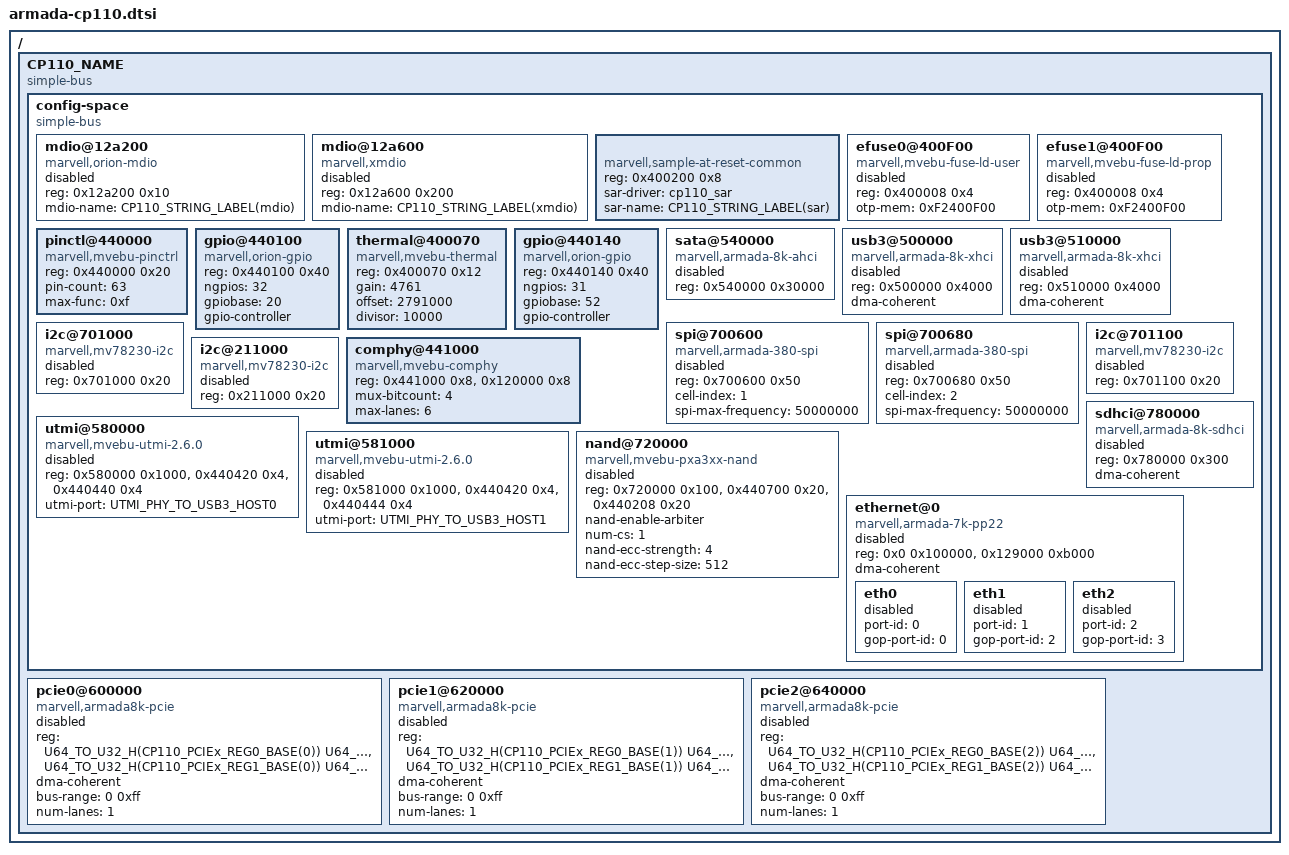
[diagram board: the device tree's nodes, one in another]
// SPDX-License-Identifier: GPL-2.0+
/*
 * Copyright (C) 2018 Marvell International Ltd.
 */

/*
 * Generic Device Tree describing Marvell Armada CP-110 device
 */
#include <dt-bindings/comphy/comphy_data.h>

#define U64_TO_U32_H(addr)		(((addr) >> 32) & 0xffffffff)
#define U64_TO_U32_L(addr)		((addr) & 0xffffffff)

#define CP110_PCIEx_REG0_BASE(iface)	\
	(CP110_BASE + 0x600000 + (iface) * 0x20000)
#define CP110_PCIEx_REG1_BASE(iface)	\
	(CP110_PCIEx_CPU_MEM_BASE(iface) + CP110_PCIE_MEM_SIZE)
/ {
	CP110_NAME {
		#address-cells = <2>;
		#size-cells = <2>;
		compatible = "simple-bus";
		ranges;

		config-space {
			#address-cells = <1>;
			#size-cells = <1>;
			compatible = "simple-bus";
			ranges = <0x0 U64_TO_U32_H(CP110_BASE) U64_TO_U32_L(CP110_BASE) 0x2000000>;

			CP110_LABEL(mdio): mdio@12a200 {
				#address-cells = <1>;
				#size-cells = <0>;
				compatible = "marvell,orion-mdio";
				reg = <0x12a200 0x10>;
				mdio-name = CP110_STRING_LABEL(mdio);
				status = "disabled";
			};

			CP110_LABEL(xmdio): mdio@12a600 {
				#address-cells = <1>;
				#size-cells = <0>;
				compatible = "marvell,xmdio";
				reg = <0x12a600 0x200>;
				mdio-name = CP110_STRING_LABEL(xmdio);
				status = "disabled";
			};

			CP110_LABEL(sar-reg) {
				compatible = "marvell,sample-at-reset-common",
					     "marvell,sample-at-reset-cp110";
				reg = <0x400200 0x8>;
				sar-driver = "cp110_sar";
				sar-name = CP110_STRING_LABEL(sar);
				status = "okay";
			};

			CP110_LABEL(ld_efuse0): efuse0@400F00 {
				compatible = "marvell,mvebu-fuse-ld-user";
				reg = <0x400008 0x4>;
				otp-mem = <0xF2400F00>;
				status = "disabled";
			};

			CP110_LABEL(ld_efuse1): efuse1@400F00 {
				compatible = "marvell,mvebu-fuse-ld-prop";
				reg = <0x400008 0x4>;
				otp-mem = <0xF2400F00>;
				status = "disabled";
			};

			CP110_LABEL(pinctl): pinctl@440000 {
				compatible = "marvell,mvebu-pinctrl";
				reg = <0x440000 0x20>;
				pin-count = <63>;
				max-func = <0xf>;
			};

			CP110_LABEL(gpio0): gpio@440100 {
				compatible = "marvell,orion-gpio";
				reg = <0x440100 0x40>;
				ngpios = <32>;
				gpiobase = <20>;
				gpio-controller;
				#gpio-cells = <2>;
			};

			CP110_LABEL(thermal): thermal@400070 {
				compatible = "marvell,mvebu-thermal", "marvell,thermal-sensor";
				reg = <0x400070 0x12>;
				gain = <4761>;
				offset = <2791000>;
				divisor = <10000>;
				status = "okay";
			};

			CP110_LABEL(gpio1): gpio@440140 {
				compatible = "marvell,orion-gpio";
				reg = <0x440140 0x40>;
				ngpios = <31>;
				gpiobase = <52>;
				gpio-controller;
				#gpio-cells = <2>;
			};

			CP110_LABEL(sata0): sata@540000 {
				compatible = "marvell,armada-8k-ahci";
				reg = <0x540000 0x30000>;
				status = "disabled";
			};

			CP110_LABEL(usb3_0): usb3@500000 {
				compatible = "marvell,armada-8k-xhci",
					     "generic-xhci";
				reg = <0x500000 0x4000>;
				dma-coherent;
				status = "disabled";
			};

			CP110_LABEL(usb3_1): usb3@510000 {
				compatible = "marvell,armada-8k-xhci",
					     "generic-xhci";
				reg = <0x510000 0x4000>;
				dma-coherent;
				status = "disabled";
			};

			CP110_LABEL(spi0): spi@700600 {
				compatible = "marvell,armada-380-spi";
				reg = <0x700600 0x50>;
				#address-cells = <0x1>;
				#size-cells = <0x0>;
				cell-index = <1>;
				spi-max-frequency = <50000000>;
				status = "disabled";
			};

			CP110_LABEL(spi1): spi@700680 {
				compatible = "marvell,armada-380-spi";
				reg = <0x700680 0x50>;
				#address-cells = <1>;
				#size-cells = <0>;
				cell-index = <2>;
				spi-max-frequency = <50000000>;
				status = "disabled";
			};

			CP110_LABEL(i2c0): i2c@701000 {
				compatible = "marvell,mv78230-i2c";
				reg = <0x701000 0x20>;
				#address-cells = <1>;
				#size-cells = <0>;
				status = "disabled";
			};

			CP110_LABEL(i2c1): i2c@701100 {
				compatible = "marvell,mv78230-i2c";
				reg = <0x701100 0x20>;
				#address-cells = <1>;
				#size-cells = <0>;
				status = "disabled";
			};

			CP110_LABEL(mss_i2c0): i2c@211000 {
				compatible = "marvell,mv78230-i2c";
				reg = <0x211000 0x20>;
				#address-cells = <1>;
				#size-cells = <0>;
				status = "disabled";
			};

			CP110_LABEL(comphy): comphy@441000 {
				compatible = "marvell,mvebu-comphy", "marvell,comphy-cp110";
				reg = <0x441000 0x8>,
				      <0x120000 0x8>;
				mux-bitcount = <4>;
				max-lanes = <6>;
			};

			CP110_LABEL(utmi0): utmi@580000 {
				compatible = "marvell,mvebu-utmi-2.6.0";
				reg = <0x580000 0x1000>,	/* utmi-unit */
				      <0x440420 0x4>,		/* usb-cfg */
				      <0x440440 0x4>;		/* utmi-cfg */
				utmi-port = <UTMI_PHY_TO_USB3_HOST0>;
				status = "disabled";
			};

			CP110_LABEL(utmi1): utmi@581000 {
				compatible = "marvell,mvebu-utmi-2.6.0";
				reg = <0x581000 0x1000>,	/* utmi-unit */
				      <0x440420 0x4>,		/* usb-cfg */
				      <0x440444 0x4>;		/* utmi-cfg */
				utmi-port = <UTMI_PHY_TO_USB3_HOST1>;
				status = "disabled";
			};

			CP110_LABEL(sdhci0): sdhci@780000 {
				compatible = "marvell,armada-8k-sdhci";
				reg = <0x780000 0x300>;
				dma-coherent;
				status = "disabled";
			};

			CP110_LABEL(nand): nand@720000 {
				compatible = "marvell,mvebu-pxa3xx-nand";
				reg = <0x720000 0x100>,
				      <0x440700 0x20>,
				      <0x440208 0x20>;
				reg-names = "ctrl_base",
					    "flash_clock",
					    "dev_mux";
				#address-cells = <1>;

				nand-enable-arbiter;
				num-cs = <1>;
				nand-ecc-strength = <4>;
				nand-ecc-step-size = <512>;
				status = "disabled";
			};

			CP110_LABEL(ethernet): ethernet@0 {
				compatible = "marvell,armada-7k-pp22";
				reg = <0x0 0x100000>, <0x129000 0xb000>;
				status = "disabled";
				dma-coherent;

				CP110_LABEL(eth0): eth0 {
					port-id = <0>;
					gop-port-id = <0>;
					status = "disabled";
				};

				CP110_LABEL(eth1): eth1 {
					port-id = <1>;
					gop-port-id = <2>;
					status = "disabled";
				};

				CP110_LABEL(eth2): eth2 {
					port-id = <2>;
					gop-port-id = <3>;
					status = "disabled";
				};
			};
		};

		CP110_LABEL(pcie0): pcie0@600000 {
			compatible = "marvell,armada8k-pcie", "snps,dw-pcie";
			reg =
			   <U64_TO_U32_H(CP110_PCIEx_REG0_BASE(0)) U64_TO_U32_L(CP110_PCIEx_REG0_BASE(0)) 0 0x10000>,
			   /* Last 512KB of mem space */
			   <U64_TO_U32_H(CP110_PCIEx_REG1_BASE(0)) U64_TO_U32_L(CP110_PCIEx_REG1_BASE(0)) 0 0x80000>;
			reg-names = "ctrl", "config";
			#address-cells = <3>;
			#size-cells = <2>;
			device_type = "pci";
			dma-coherent;

			bus-range = <0 0xff>;
			ranges =
				/* downstream I/O */
				<0x81000000 U64_TO_U32_H(CP110_PCIEx_BUS_IO_BASE(0))
				U64_TO_U32_L(CP110_PCIEx_BUS_IO_BASE(0)) U64_TO_U32_H(CP110_PCIEx_CPU_IO_BASE(0))
				U64_TO_U32_L(CP110_PCIEx_CPU_IO_BASE(0)) 0 0x10000
				/* non-prefetchable memory */
				CP110_PCIE_BUS_MEM_CFG U64_TO_U32_H(CP110_PCIEx_BUS_MEM_BASE(0))
				U64_TO_U32_L(CP110_PCIEx_BUS_MEM_BASE(0)) U64_TO_U32_H(CP110_PCIEx_CPU_MEM_BASE(0))
				U64_TO_U32_L(CP110_PCIEx_CPU_MEM_BASE(0)) U64_TO_U32_H(CP110_PCIE_MEM_SIZE)
				U64_TO_U32_L(CP110_PCIE_MEM_SIZE)>;
			num-lanes = <1>;
			status = "disabled";
		};

		CP110_LABEL(pcie1): pcie1@620000 {
			compatible = "marvell,armada8k-pcie", "snps,dw-pcie";
			reg =
			   <U64_TO_U32_H(CP110_PCIEx_REG0_BASE(1)) U64_TO_U32_L(CP110_PCIEx_REG0_BASE(1)) 0 0x10000>,
			   /* Last 512KB of mem space */
			   <U64_TO_U32_H(CP110_PCIEx_REG1_BASE(1)) U64_TO_U32_L(CP110_PCIEx_REG1_BASE(1)) 0 0x80000>;
			reg-names = "ctrl", "config";
			#address-cells = <3>;
			#size-cells = <2>;
			device_type = "pci";
			dma-coherent;

			bus-range = <0 0xff>;
			ranges =
				/* downstream I/O */
				<0x81000000 U64_TO_U32_H(CP110_PCIEx_BUS_IO_BASE(1))
				U64_TO_U32_L(CP110_PCIEx_BUS_IO_BASE(1)) U64_TO_U32_H(CP110_PCIEx_CPU_IO_BASE(1))
				U64_TO_U32_L(CP110_PCIEx_CPU_IO_BASE(1)) 0 0x10000
				/* non-prefetchable memory */
				CP110_PCIE_BUS_MEM_CFG U64_TO_U32_H(CP110_PCIEx_BUS_MEM_BASE(1))
				U64_TO_U32_L(CP110_PCIEx_BUS_MEM_BASE(1)) U64_TO_U32_H(CP110_PCIEx_CPU_MEM_BASE(1))
				U64_TO_U32_L(CP110_PCIEx_CPU_MEM_BASE(1)) U64_TO_U32_H(CP110_PCIE_MEM_SIZE)
				U64_TO_U32_L(CP110_PCIE_MEM_SIZE)>;
			num-lanes = <1>;
			status = "disabled";
		};

		CP110_LABEL(pcie2): pcie2@640000 {
			compatible = "marvell,armada8k-pcie", "snps,dw-pcie";
			reg =
			   <U64_TO_U32_H(CP110_PCIEx_REG0_BASE(2)) U64_TO_U32_L(CP110_PCIEx_REG0_BASE(2)) 0 0x10000>,
			   /* Last 64KB of mem space */
			   <U64_TO_U32_H(CP110_PCIEx_REG1_BASE(2)) U64_TO_U32_L(CP110_PCIEx_REG1_BASE(2)) 0 0x80000>;
			reg-names = "ctrl", "config";
			#address-cells = <3>;
			#size-cells = <2>;
			device_type = "pci";
			dma-coherent;

			bus-range = <0 0xff>;
			ranges =
				/* downstream I/O */
				<0x81000000 U64_TO_U32_H(CP110_PCIEx_BUS_IO_BASE(2))
				U64_TO_U32_L(CP110_PCIEx_BUS_IO_BASE(2)) U64_TO_U32_H(CP110_PCIEx_CPU_IO_BASE(2))
				U64_TO_U32_L(CP110_PCIEx_CPU_IO_BASE(2)) 0 0x10000
				/* non-prefetchable memory */
				CP110_PCIE_BUS_MEM_CFG U64_TO_U32_H(CP110_PCIEx_BUS_MEM_BASE(2))
				U64_TO_U32_L(CP110_PCIEx_BUS_MEM_BASE(2)) U64_TO_U32_H(CP110_PCIEx_CPU_MEM_BASE(2))
				U64_TO_U32_L(CP110_PCIEx_CPU_MEM_BASE(2)) U64_TO_U32_H(CP110_PCIE_MEM_SIZE)
				U64_TO_U32_L(CP110_PCIE_MEM_SIZE)>;
			num-lanes = <1>;
			status = "disabled";
		};
	};
};
